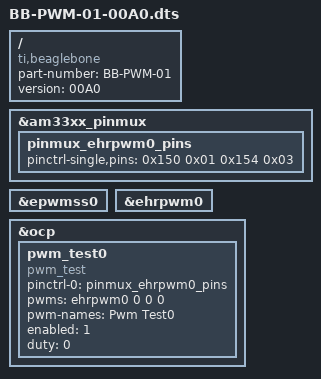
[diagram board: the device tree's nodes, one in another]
/dts-v1/;
/plugin/;
/ {
	compatible = "ti,beaglebone","ti,beaglebone-black";

	/* Identification */
	part-number = "BB-PWM-01";
	version = "00A0";

	fragment@0 {
		target = <&am33xx_pinmux>;
		__overlay__ {
			pinmux_ehrpwm0_pins: pinmux_ehrpwm0_pins {
				pinctrl-single,pins = <
					0x150 0x01
					0x154 0x03
				>;
			};
		};
	};

	fragment@1 {
		target = <&epwmss0>;
		__overlay__ {
			status = "okay";
		};
	};
	
	fragment@2 {
		target = <&ehrpwm0>;
		__overlay__ {
			status = "okay";
		};
	};

	fragment@3 {
		target = <&ocp>;
		__overlay__ {

			pwm_test0 {
				compatible = "pwm_test";
				pinctrl-names = "default";
				pinctrl-0 = <&pinmux_ehrpwm0_pins>;
				pwms = <&ehrpwm0 0 0 0>;
				pwm-names = "Pwm Test0";
				enabled = <1>;
				duty = <0>;
				status = "okay";
			};
		};
	};
};

